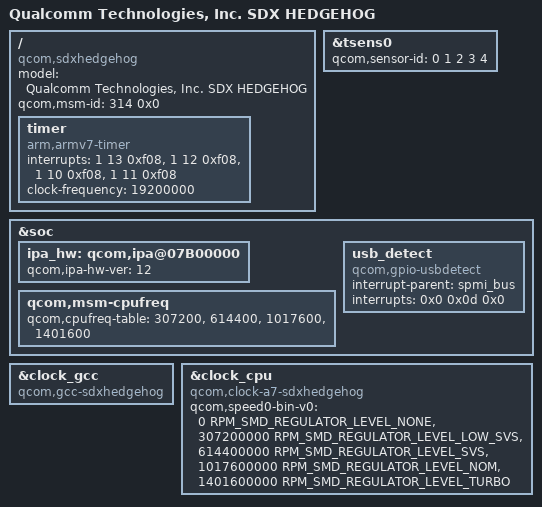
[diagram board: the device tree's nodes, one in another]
/* Copyright (c) 2016-2017, The Linux Foundation. All rights reserved.
 *
 * This program is free software; you can redistribute it and/or modify
 * it under the terms of the GNU General Public License version 2 and
 * only version 2 as published by the Free Software Foundation.
 *
 * This program is distributed in the hope that it will be useful,
 * but WITHOUT ANY WARRANTY; without even the implied warranty of
 * MERCHANTABILITY or FITNESS FOR A PARTICULAR PURPOSE.  See the
 * GNU General Public License for more details.
 */

/ {
	model = "Qualcomm Technologies, Inc. SDX HEDGEHOG";
	compatible = "qcom,sdxhedgehog";
	qcom,msm-id = <314 0x0>;

	timer {
		compatible = "arm,armv7-timer";
		interrupts = <1 13 0xf08>,
			<1 12 0xf08>,
			<1 10 0xf08>,
			<1 11 0xf08>;
		clock-frequency = <19200000>;
	};

};

&tsens0 {
	qcom,sensor-id = <0 1 2 3 4>;
};

&soc {
	ipa_hw: qcom,ipa@07B00000 {
		qcom,ipa-hw-ver = <12>; /* IPA core version = IPAv3.5 */
		/delete-property/qcom,use-rg10-limitation-mitigation;
	};

	qcom,msm-cpufreq {
		qcom,cpufreq-table =
			<  307200 >,
			<  614400 >,
			< 1017600 >,
			< 1401600 >;
	};

	usb_detect {
		compatible = "qcom,gpio-usbdetect";
		interrupt-parent = <&spmi_bus>;
		interrupts = <0x0 0x0d 0x0>;
		interrupt-names = "vbus_det_irq";
	};
};

&clock_gcc {
	compatible = "qcom,gcc-sdxhedgehog";
};

&clock_cpu  {
	compatible = "qcom,clock-a7-sdxhedgehog";

	qcom,speed0-bin-v0 =
		<         0 RPM_SMD_REGULATOR_LEVEL_NONE >,
		< 307200000 RPM_SMD_REGULATOR_LEVEL_LOW_SVS >,
		< 614400000 RPM_SMD_REGULATOR_LEVEL_SVS >,
		< 1017600000 RPM_SMD_REGULATOR_LEVEL_NOM >,
		< 1401600000 RPM_SMD_REGULATOR_LEVEL_TURBO >;
};

#include "sdxhedgehog-bus.dtsi"
